# MCAN register map
Vendor: Texas Instruments
Peripheral module from a debugger description file (folder am574x).
Registers are 32-bit, access per field, reset 0x0 unless marked. A register's access mark holds for its fields unless they carry their own. Offsets are as the file gives them; lines under a group give offsets from that group; [hi:lo] are bit positions; {n}, {i} and the like mark numbered series; 'fields as' and 'values as' point back to an identical list; <NAME> marks a mode.

## MCAN (part 1 of 2)
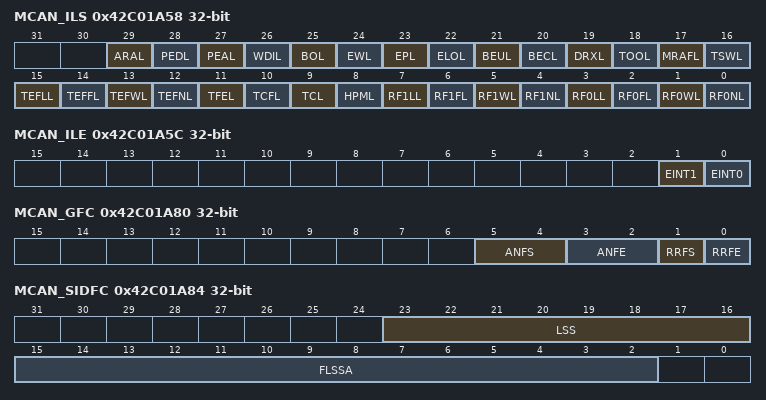
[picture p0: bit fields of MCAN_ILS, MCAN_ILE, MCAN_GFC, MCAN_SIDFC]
0x42C01A58 MCAN_ILS — Interrupt Line SelectThe Interrupt Line Select register assigns an interrupt generated by a specific interrupt flag from the Interrupt Register to one of the two module interrupt lines. For interrupt generation the respective interrupt line has to be enabled via the
  [29] ARAL rw — Access to Reserved Address Line 0x0: Interrupt assigned to interrupt line INT0 0x1: Interrupt assigned to interrupt line INT1
  [28] PEDL rw — Protocol Error in Data Phase Line 0x0: Interrupt assigned to interrupt line INT0 0x1: Interrupt assigned to interrupt line INT1
  [27] PEAL rw — Protocol Error in Arbitration Phase Line 0x0: Interrupt assigned to interrupt line INT0 0x1: Interrupt assigned to interrupt line INT1
  [26] WDIL rw — Watchdog Interrupt Line 0x0: Interrupt assigned to interrupt line INT0 0x1: Interrupt assigned to interrupt line INT1
  [25] BOL rw — Bus_Off Status Interrupt Line 0x0: Interrupt assigned to interrupt line INT0 0x1: Interrupt assigned to interrupt line INT1
  [24] EWL rw — Warning Status Interrupt Line 0x0: Interrupt assigned to interrupt line INT0 0x1: Interrupt assigned to interrupt line INT1
  [23] EPL rw — Error Passive Interrupt Line 0x0: Interrupt assigned to interrupt line INT0 0x1: Interrupt assigned to interrupt line INT1
  [22] ELOL rw — Error Logging Overflow Interrupt Line 0x0: Interrupt assigned to interrupt line INT0 0x1: Interrupt assigned to interrupt line INT1
  [21] BEUL rw — Bit Error Uncorrected Interrupt Line 0x0: Interrupt assigned to interrupt line INT0 0x1: Interrupt assigned to interrupt line INT1
  [20] BECL rw — Bit Error Corrected Interrupt Line 0x0: Interrupt assigned to interrupt line INT0 0x1: Interrupt assigned to interrupt line INT1
  [19] DRXL rw — Message stored to Dedicated Rx Buffer Interrupt Line 0x0: Interrupt assigned to interrupt line INT0 0x1: Interrupt assigned to interrupt line INT1
  [18] TOOL rw — Timeout Occurred Interrupt Line 0x0: Interrupt assigned to interrupt line INT0 0x1: Interrupt assigned to interrupt line INT1
  [17] MRAFL rw — Message RAM Access Failure Interrupt Line 0x0: Interrupt assigned to interrupt line INT0 0x1: Interrupt assigned to interrupt line INT1
  [16] TSWL rw — Timestamp Wraparound Interrupt Line 0x0: Interrupt assigned to interrupt line INT0 0x1: Interrupt assigned to interrupt line INT1
  [15] TEFLL rw — Tx Event FIFO Event Lost Interrupt Line 0x0: Interrupt assigned to interrupt line INT0 0x1: Interrupt assigned to interrupt line INT1
  [14] TEFFL rw — Tx Event FIFO Full Interrupt Line 0x0: Interrupt assigned to interrupt line INT0 0x1: Interrupt assigned to interrupt line INT1
  [13] TEFWL rw — Tx Event FIFO Watermark Reached Interrupt Line 0x0: Interrupt assigned to interrupt line INT0 0x1: Interrupt assigned to interrupt line INT1
  [12] TEFNL rw — Tx Event FIFO New Entry Interrupt Line 0x0: Interrupt assigned to interrupt line INT0 0x1: Interrupt assigned to interrupt line INT1
  [11] TFEL rw — Tx FIFO Empty Interrupt Line 0x0: Interrupt assigned to interrupt line INT0 0x1: Interrupt assigned to interrupt line INT1
  [10] TCFL rw — Transmission Cancellation Finished Interrupt Line 0x0: Interrupt assigned to interrupt line INT0 0x1: Interrupt assigned to interrupt line INT1
  [9] TCL rw — Transmission Completed Interrupt Line 0x0: Interrupt assigned to interrupt line INT0 0x1: Interrupt assigned to interrupt line INT1
  [8] HPML rw — High Priority Message Interrupt Line 0x0: Interrupt assigned to interrupt line INT0 0x1: Interrupt assigned to interrupt line INT1
  [7] RF1LL rw — Rx FIFO 1 Message Lost Interrupt Line 0x0: Interrupt assigned to interrupt line INT0 0x1: Interrupt assigned to interrupt line INT1
  [6] RF1FL rw — Rx FIFO 1 Full Interrupt Line 0x0: Interrupt assigned to interrupt line INT0 0x1: Interrupt assigned to interrupt line INT1
  [5] RF1WL rw — Rx FIFO 1 Watermark Reached Interrupt Line 0x0: Interrupt assigned to interrupt line INT0 0x1: Interrupt assigned to interrupt line INT1
  [4] RF1NL rw — Rx FIFO 1 New Message Interrupt Line 0x0: Interrupt assigned to interrupt line INT0 0x1: Interrupt assigned to interrupt line INT1
  [3] RF0LL rw — Rx FIFO 0 Message Lost Interrupt Line 0x0: Interrupt assigned to interrupt line INT0 0x1: Interrupt assigned to interrupt line INT1
  [2] RF0FL rw — Rx FIFO 0 Full Interrupt Line 0x0: Interrupt assigned to interrupt line INT0 0x1: Interrupt assigned to interrupt line INT1
  [1] RF0WL rw — Rx FIFO 0 Watermark Reached Interrupt Line 0x0: Interrupt assigned to interrupt line INT0 0x1: Interrupt assigned to interrupt line INT1
  [0] RF0NL rw — Rx FIFO 0 New Message Interrupt Line 0x0: Interrupt assigned to interrupt line INT0 0x1: Interrupt assigned to interrupt line INT1
0x42C01A5C MCAN_ILE — Interrupt Line Enable Enable/disable interrupt lines INT0/INT1. Each of the two interrupt lines to the Host CPU can be enabled/disabled separately by programming the
  [1] EINT1 rw — Enable Interrupt Line 1 0x0: Interrupt line INT1 disabled 0x1: Interrupt line INT1 enabled
  [0] EINT0 rw — Enable Interrupt Line 0 0x0: Interrupt line INT0 disabled 0x1: Interrupt line INT0 enabled
0x42C01A80 MCAN_GFC — Global Filter Configuration Handling of non-matching frames and remote frames. Global settings for Message ID filtering. The Global Filter Configuration controls the filter path for standard and extended messages (see
  [5:4] ANFS rw — Accept Non-matching Frames Standard Defines how received messages with 11-bit IDs that do not match any element of the filter list are treated. 0x0: Accept in Rx FIFO 0 0x1: Accept in Rx FIFO 1 0x2: Reject 0x3: Reject
  [3:2] ANFE rw — Accept Non-matching Frames Extended Defines how received messages with 29-bit IDs that do not match any element of the filter list are treated. 0x0: Accept in Rx FIFO 0 0x1: Accept in Rx FIFO 1 0x2: Reject 0x3: Reject
  [1] RRFS rw — Reject Remote Frames Standard 0x0: Filter remote frames with 11-bit standard IDs 0x1: Reject all remote frames with 11-bit standard IDs
  [0] RRFE rw — Reject Remote Frames Extended 0x0: Filter remote frames with 29-bit extended IDs 0x1: Reject all remote frames with 29-bit extended IDs
0x42C01A84 MCAN_SIDFC — Standard ID Filter Configuration Number of filter elements, pointer to start of filter list. Settings for 11-bit standard Message ID filtering. The Standard ID Filter Configuration controls the filter path for standard messages (see
  [23:16] LSS rw — List Size Standard 0x0: No standard Message ID filter 0x1-0x80 (1-128): Number of standard Message ID filter elements &gt; 0x80 (128): Values greater than 128 are interpreted as 128
  [15:2] FLSSA rw — Filter List Standard Start Address Start address of standard Message ID filter list (32-bit word address, see
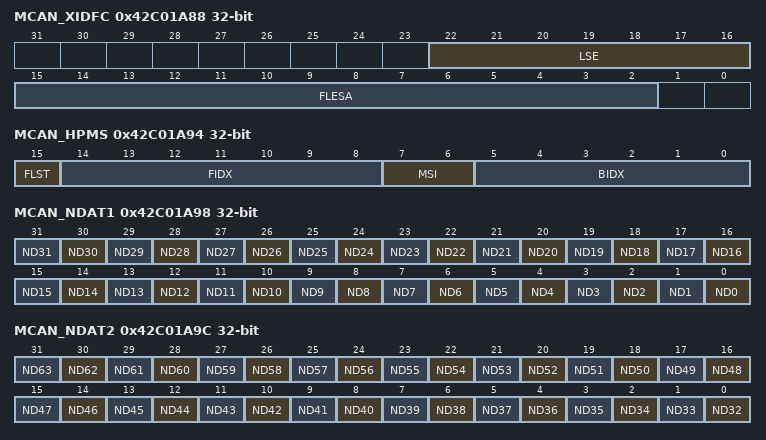
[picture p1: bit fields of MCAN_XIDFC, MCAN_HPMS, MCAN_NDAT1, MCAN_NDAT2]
0x42C01A88 MCAN_XIDFC — Extended ID Filter Configuration Number of filter elements, pointer to start of filter list. Settings for 29-bit extended Message ID filtering. The Extended ID Filter Configuration controls the filter path for standard messages (see
  [22:16] LSE rw — List Size Extended 0x0: No extended Message ID filter 0x1-0x40 (1-64): Number of extended Message ID filter elements &gt; 0x40 (64): Values greater than 64 are interpreted as 64
  [15:2] FLESA rw — Filter List Extended Start Address Start address of extended Message ID filter list (32-bit word address, see
0x42C01A90 MCAN_XIDAM reset 0x1FFFFFFF — Extended ID AND Mask 29-bit logical AND mask for J1939.
  [28:0] EIDM rw — Extended ID Mask For acceptance filtering of extended frames the Extended ID AND Mask is ANDed with the Message ID of a received frame. Intended for masking of 29-bit IDs in SAE J1939. With the reset value of all bits set to one the mask is not active.
0x42C01A94 MCAN_HPMS ro — High Priority Message Status Status monitoring of incoming high priority messages. This register is updated every time a Message ID filter element configured to generate a priority event matches. This can be used to monitor the status of incoming high priority messages and to enable fast access to these messages.
  [15] FLST — Filter List Indicates the filter list of the matching filter element. 0x0: Standard Filter List 0x1: Extended Filter List
  [14:8] FIDX — Filter Index Index of matching filter element. Range is 0 to
  [7:6] MSI — Message Storage Indicator 0x0: No FIFO selected 0x1: FIFO message lost 0x2: Message stored in FIFO 0 0x3: Message stored in FIFO 1
  [5:0] BIDX — Buffer Index Index of Rx FIFO element to which the message was stored. Only valid when the
0x42C01A98 MCAN_NDAT1 access not given — New Data 1 NewDat flags of dedicated Rx buffers 0-31. The register holds the New Data flags of Rx Buffers 0 to 31. The flags are set when the respective Rx Buffer has been updated from a received frame. The flags remain set until the Host CPU clears them. Aflag is cleared by writing a ’1’ to the corresponding bit position. Writing a ’0’ has no effect. Ahard reset will clear the register.
  [n] ND{n} (n=0..31) — New Data 0x0: Rx Buffer not updated 0x1: Rx Buffer updated from new message (access RW1TC)
0x42C01A9C MCAN_NDAT2 access not given — New Data 2 NewDat flags of dedicated Rx buffers 32-63. The register holds the New Data flags of Rx Buffers 32 to 63. The flags are set when the respective Rx Buffer has been updated from a received frame. The flags remain set until the Host CPU clears them. Aflag is cleared by writing a ’1’ to the corresponding bit position. Writing a ’0’ has no effect. Ahard reset will clear the register.
  [n-32] ND{n} (n=32..63) — New Data 0x0: Rx Buffer not updated 0x1: Rx Buffer updated from new message (access RW1TC)
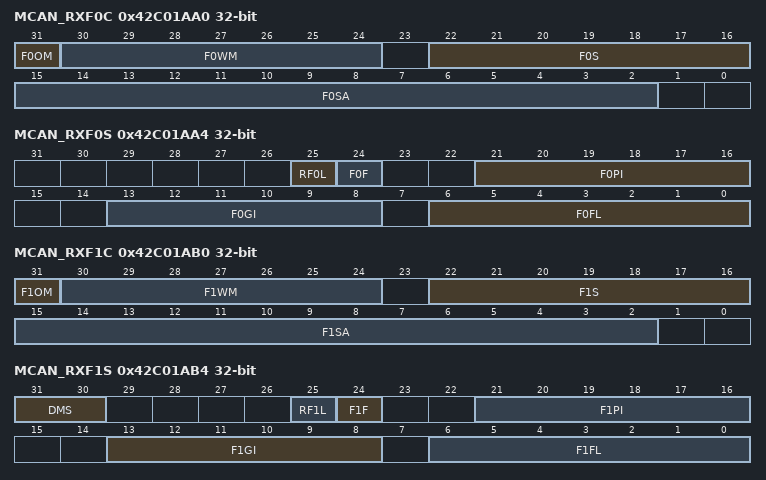
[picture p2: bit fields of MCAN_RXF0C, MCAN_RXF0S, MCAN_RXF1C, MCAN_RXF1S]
0x42C01AA0 MCAN_RXF0C — Rx FIFO 0 Configuration FIFO 0 operation mode, watermark, size and start address.
  [31] F0OM rw — FIFO 0 Operation Mode FIFO 0 can be operated in blocking or in overwrite mode (see 0x0: FIFO 0 blocking mode 0x1: FIFO 0 overwrite mode
  [30:24] F0WM rw — Rx FIFO 0 Watermark 0x0: Watermark interrupt disabled 0x1-0x40 (1-64): Level for Rx FIFO 0 watermark interrupt ( &gt; 0x40 (64): Watermark interrupt disabled
  [22:16] F0S rw — Rx FIFO 0 Size 0x0: No Rx FIFO 0 0x1-0x40 (1-64): Number of Rx FIFO 0 elements &gt; 0x40 (64): Values greater than 64 are interpreted as 64 The Rx FIFO 0 elements are indexed from 0 to
  [15:2] F0SA rw — Rx FIFO 0 Start Address Start address of Rx FIFO 0 in Message RAM (32-bit word address, see
0x42C01AA4 MCAN_RXF0S ro — Rx FIFO 0 Status FIFO 0 message lost/full indication, put index, get index and fill level.
  [25] RF0L — Rx FIFO 0 Message Lost This bit is a copy of interrupt flag 0x0: No Rx FIFO 0 message lost 0x1: Rx FIFO 0 message lost, also set after write attempt to Rx FIFO 0 of size zero
  [24] F0F — Rx FIFO 0 Full 0x0: Rx FIFO 0 not full 0x1: Rx FIFO 0 full
  [21:16] F0PI — Rx FIFO 0 Put Index Rx FIFO 0 write index pointer, range 0 to 63.
  [13:8] F0GI — Rx FIFO 0 Get Index Rx FIFO 0 read index pointer, range 0 to 63.
  [6:0] F0FL — Rx FIFO 0 Fill Level Number of elements stored in Rx FIFO 0, range 0 to 64.
0x42C01AA8 MCAN_RXF0A — Rx FIFO 0 Acknowledge FIFO 0 acknowledge last index of read buffers, updates get index and fill level.
  [5:0] F0AI rw — Rx FIFO 0 Acknowledge Index After the Host CPU has read a message or a sequence of messages from Rx FIFO 0 it has to write the buffer index of the last element read from Rx FIFO 0 to the
0x42C01AAC MCAN_RXBC — Rx Buffer Configuration Start address of Rx buffer section.
  [15:2] RBSA rw — Rx Buffer Start Address Configures the start address of the Rx Buffers section in the Message RAM Also used to reference debug messages A,B,C.
0x42C01AB0 MCAN_RXF1C — Rx FIFO 1 Configuration FIFO 1 operation mode, watermark, size and start address.
  [31] F1OM rw — FIFO 1 Operation Mode FIFO 1 can be operated in blocking or in overwrite mode (see 0x0: FIFO 1 blocking mode 0x1: FIFO 1 overwrite mode
  [30:24] F1WM rw — Rx FIFO 1 Watermark 0x0: Watermark interrupt disabled 0x1-0x40 (1-64): Level for Rx FIFO 1 watermark interrupt ( &gt; 0x40 (64): Watermark interrupt disabled
  [22:16] F1S rw — Rx FIFO 1 Size 0x0: No Rx FIFO 1 0x1-0x40 (1-64): Number of Rx FIFO 1 elements &gt; 0x40 (64): Values greater than 64 are interpreted as 64 The Rx FIFO 1 elements are indexed from 0 to
  [15:2] F1SA rw — Rx FIFO 1 Start Address Start address of Rx FIFO 1 in Message RAM (32-bit word address, see
0x42C01AB4 MCAN_RXF1S ro — Rx FIFO 1 Status FIFO 1 message lost/full indication, put index, get index and fill level.
  [31:30] DMS — Debug Message Status 0x0: Idle state, wait for reception of debug messages, DMA request is cleared 0x1: Debug message A received 0x2: Debug messages A, B received 0x3: Debug messages A, B, C received,
  [25] RF1L — Rx FIFO 1 Message Lost This bit is a copy of interrupt flag 0x0: No Rx FIFO 1 message lost 0x1: Rx FIFO 1 message lost, also set after write attempt to Rx FIFO 1 of size zero
  [24] F1F — Rx FIFO 1 Full 0x0: Rx FIFO 1 not full 0x1: Rx FIFO 1 full
  [21:16] F1PI — Rx FIFO 1 Put Index Rx FIFO 1 write index pointer, range 0 to 63.
  [13:8] F1GI — Rx FIFO 1 Get Index Rx FIFO 1 read index pointer, range 0 to 63.
  [6:0] F1FL — Rx FIFO 1 Fill Level Number of elements stored in Rx FIFO 1, range 0 to 64.
0x42C01AB8 MCAN_RXF1A — Rx FIFO 1 Acknowledge FIFO 1 acknowledge last index of read buffers, updates get index and fill level.
  [5:0] F1AI rw — Rx FIFO 1 Acknowledge Index After the Host CPU has read a message or a sequence of messages from Rx FIFO 1 it has to write the buffer index of the last element read from Rx FIFO 1 to the
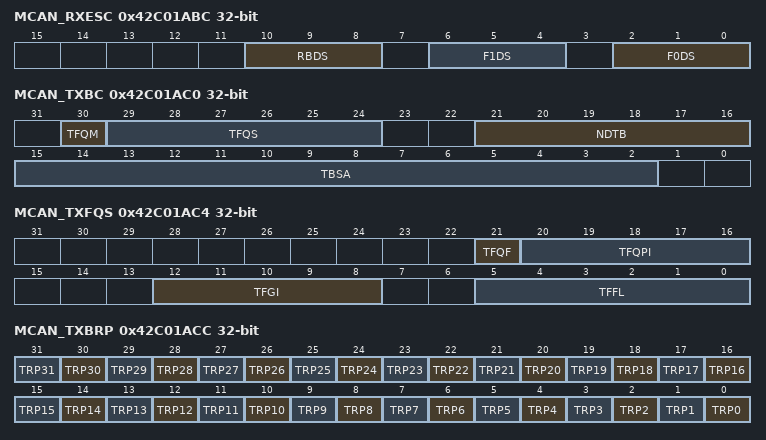
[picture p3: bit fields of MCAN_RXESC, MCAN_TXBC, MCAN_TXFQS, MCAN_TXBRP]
0x42C01ABC MCAN_RXESC — Rx Buffer/FIFO Element Size Configuration Configure data field size for storage of accepted frames.
  [10:8] RBDS rw — Rx Buffer Data Field Size 0x0: 8 byte data field 0x1: 12 byte data field 0x2: 16 byte data field 0x3: 20 byte data field 0x4: 24 byte data field 0x5: 32 byte data field 0x6: 48 byte data field 0x7: 64 byte data field
  [6:4] F1DS rw — Rx FIFO 1 Data Field Size 0x0: 8 byte data field 0x1: 12 byte data field 0x2: 16 byte data field 0x3: 20 byte data field 0x4: 24 byte data field 0x5: 32 byte data field 0x6: 48 byte data field 0x7: 64 byte data field
  [2:0] F0DS rw — Rx FIFO 0 Data Field Size 0x0: 8 byte data field 0x1: 12 byte data field 0x2: 16 byte data field 0x3: 20 byte data field 0x4: 24 byte data field 0x5: 32 byte data field 0x6: 48 byte data field 0x7: 64 byte data field
0x42C01AC0 MCAN_TXBC — Tx Buffer Configuration Configure Tx FIFO/Queue mode, Tx FIFO/Queue size, number of dedicated Tx buffers, Tx buffer start address.
  [30] TFQM rw — Tx FIFO/Queue Mode 0x0: Tx FIFO operation 0x1: Tx Queue operation
  [29:24] TFQS rw — Transmit FIFO/Queue Size 0x0: No Tx FIFO/Queue 0x1-0x20 (1-32): Number of Tx Buffers used for Tx FIFO/Queue &gt; 0x20 (32): Values greater than 32 are interpreted as 32
  [21:16] NDTB rw — Number of Dedicated Transmit Buffers 0x0: No Dedicated Tx Buffers 0x1-0x20 (1-32): Number of Dedicated Tx Buffers &gt; 0x20 (32): Values greater than 32 are interpreted as 32
  [15:2] TBSA rw — Tx Buffers Start Address Start address of Tx Buffers section in Message RAM (32-bit word address, see
0x42C01AC4 MCAN_TXFQS ro — Tx FIFO/Queue Status Tx FIFO/Queue full indication and put index, Tx FIFO get index and fill level. The Tx FIFO/Queue status is related to the pending Tx requests listed in the
  [21] TFQF — Tx FIFO/Queue Full 0x0: Tx FIFO/Queue not full 0x1: Tx FIFO/Queue full
  [20:16] TFQPI — Tx FIFO/Queue Put Index Tx FIFO/Queue write index pointer, range 0 to 31.
  [12:8] TFGI — Tx FIFO Get Index Tx FIFO read index pointer, range 0 to 31. Read as zero when Tx Queue operation is configured (
  [5:0] TFFL — Tx FIFO Free Level Number of consecutive free Tx FIFO elements starting from the
0x42C01AC8 MCAN_TXESC — Tx Buffer Element Size Configuration Configure data field size for frame transmission. Configures the number of data bytes belonging to a Tx Buffer element. Data field sizes > 8 bytes are intended for CAN FD operation only.
  [2:0] TBDS rw — Tx Buffer Data Field Size 0x0: 8 byte data field 0x1: 12 byte data field 0x2: 16 byte data field 0x3: 20 byte data field 0x4: 24 byte data field 0x5: 32 byte data field 0x6: 48 byte data field 0x7: 64 byte data field
0x42C01ACC MCAN_TXBRP ro — Tx Buffer Request Pending Tx buffers with pending transmission request. Each Tx Buffer has its own Transmission Request Pending bit. The bits are set via the The A cancellation request resets the corresponding transmission request pending bit of register the After a cancellation has been requested, a finished cancellation is signalled via the • after successful transmission together with the corresponding • when the transmission has not yet been started at the point of cancellation • when the transmission has been aborted due to lost arbitration • when an error occurred during frame transmission In DAR mode all transmissions are automatically cancelled if they are not successful. The corresponding
  [n] TRP{n} (n=0..31) — Transmission Request Pending 0x0: No transmission request pending 0x1: Transmission request pending
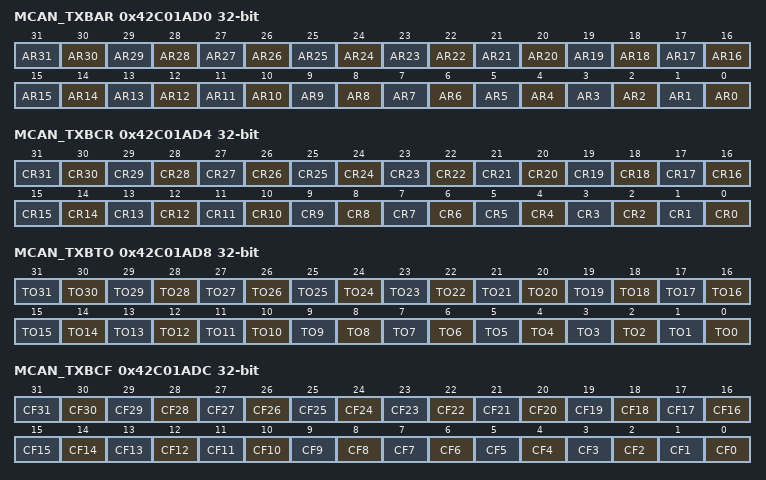
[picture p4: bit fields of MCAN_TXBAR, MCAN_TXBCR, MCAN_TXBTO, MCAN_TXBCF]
0x42C01AD0 MCAN_TXBAR access not given — Tx Buffer Add Request Add transmission requests. Each Tx Buffer has its own Add Request bit. Writing a ‘1’ will set the corresponding Add Request bit; writing a ‘0’ has no impact. This enables the Host CPU to set transmission requests for multiple Tx Buffers with one write to the
  [n] AR{n} (n=0..31) — Add Request 0x0: No transmission request added 0x1: Transmission requested added (access RW1TC)
0x42C01AD4 MCAN_TXBCR access not given — Tx Buffer Cancellation Request Request cancellation of pending transmissions. Each Tx Buffer has its own Cancellation Request bit. Writing a ‘1’ will set the corresponding Cancellation Request bit; writing a ‘0’ has no impact. This enables the Host CPU to set cancellation requests for multiple Tx Buffers with one write to the
  [n] CR{n} (n=0..31) — Cancellation Request 0x0: No cancellation pending 0x1: Cancellation pending (access RW1TC)
0x42C01AD8 MCAN_TXBTO ro — Tx Buffer Transmission Occurred Signals successful transmissions, set when corresponding flag is cleared. Each Tx Buffer has its own Transmission Occurred bit. The bits are set when the corresponding
  [n] TO{n} (n=0..31) — Transmission Occurred 0x0: No transmission occurred 0x1: Transmission occurred
0x42C01ADC MCAN_TXBCF ro — Tx Buffer Cancellation Finished Signals successful transmit cancellation, set when corresponding TXBRP flag is cleared after cancellation request. Each Tx Buffer has its own Cancellation Finished bit. The bits are set when the corresponding
  [n] CF{n} (n=0..31) — Cancellation Finished 0x0: No transmit buffer cancellation 0x1: Transmit buffer cancellation finished
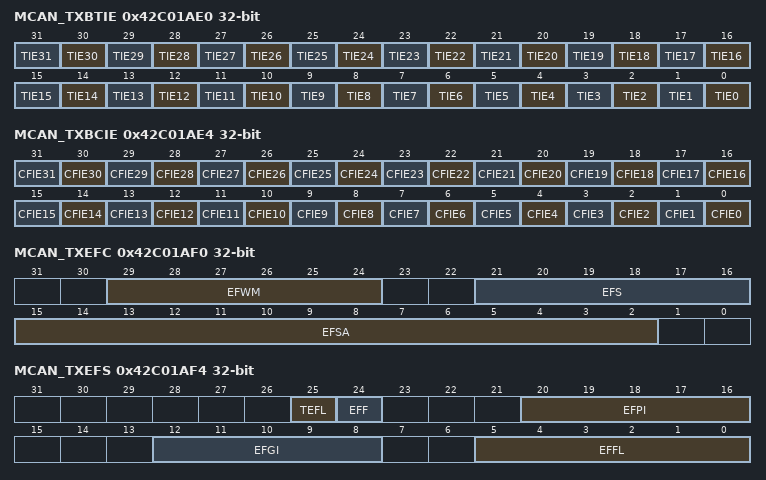
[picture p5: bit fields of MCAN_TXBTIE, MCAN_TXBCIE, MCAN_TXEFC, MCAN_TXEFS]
0x42C01AE0 MCAN_TXBTIE rw — Tx Buffer Transmission Interrupt Enable Enable transmit interrupts for selected Tx buffers.
  [n] TIE{n} (n=0..31) — Transmission Interrupt Enable 0x0: Transmission interrupt disabled 0x1: Transmission interrupt enable
0x42C01AE4 MCAN_TXBCIE rw — Tx Buffer Cancellation Finished Interrupt Enable Enable cancellation finished interrupts for selected Tx buffers.
  [n] CFIE{n} (n=0..31) — Cancellation Finished Interrupt Enable 0x0: Cancellation finished interrupt disabled 0x1: Cancellation finished interrupt enabled
0x42C01AF0 MCAN_TXEFC — Tx Event FIFO Configuration Tx event FIFO watermark, size and start address.
  [29:24] EFWM rw — Event FIFO Watermark 0x0: Watermark interrupt disabled 0x1-0x20 (1-32): Level for Tx Event FIFO watermark interrupt ( &gt; 0x20 (32): Watermark interrupt disabled
  [21:16] EFS rw — Event FIFO Size 0x0: Tx Event FIFO disabled 0x1-0x20 (1-32): Number of Tx Event FIFO elements &gt; 0x20 (32): Values greater than 32 are interpreted as 32 The Tx Event FIFO elements are indexed from 0 to
  [15:2] EFSA rw — Event FIFO Start Address Start address of Tx Event FIFO in Message RAM (32-bit word address, see
0x42C01AF4 MCAN_TXEFS ro — Tx Event FIFO Status Tx event FIFO element lost/full indication, put index, get index, and fill level.
  [25] TEFL — This bit is a copy of interrupt flag 0x0: No Tx Event FIFO element lost 0x1: Tx Event FIFO element lost, also set after write attempt to Tx Event FIFO of size zero.
  [24] EFF — Event FIFO Full 0x0: Tx Event FIFO not full 0x1: Tx Event FIFO full
  [20:16] EFPI — Event FIFO Put Index Tx Event FIFO write index pointer, range 0 to 31.
  [12:8] EFGI — Event FIFO Get Index Tx Event FIFO read index pointer, range 0 to 31.
  [5:0] EFFL — Event FIFO Fill Level Number of elements stored in Tx Event FIFO, range 0 to 32.
0x42C01AF8 MCAN_TXEFA — Tx Event FIFO Acknowledge Tx event FIFO acknowledge last index of read elements, updates get index and fill level.
  [4:0] EFAI rw — After the Host CPU has read an element or a sequence of elements from the Tx Event FIFO it has to write the index of the last element read from Tx Event FIFO to the
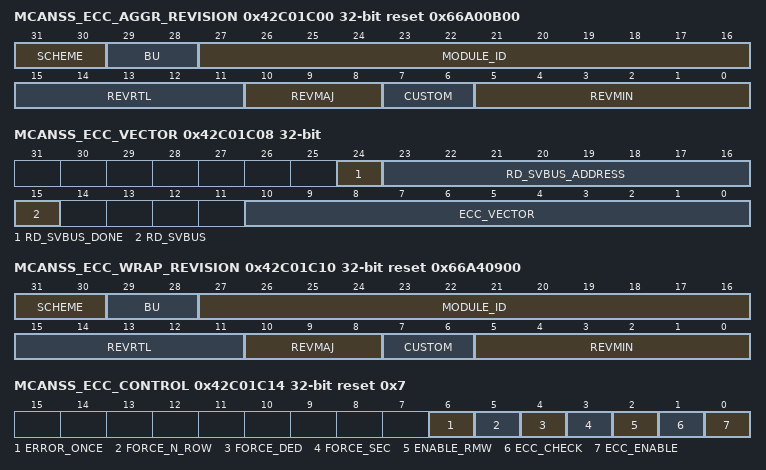
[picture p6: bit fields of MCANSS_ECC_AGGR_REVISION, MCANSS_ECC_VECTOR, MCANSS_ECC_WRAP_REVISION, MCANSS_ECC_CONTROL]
0x42C01C00 MCANSS_ECC_AGGR_REVISION ro reset 0x66A00B00 — Aggregator Revision Register Revision parameters.
  [31:30] SCHEME
  [29:28] BU — Business Unit
  [27:16] MODULE_ID
  [15:11] REVRTL — RTL version
  [10:8] REVMAJ — Major version
  [7:6] CUSTOM — Custom version
  [5:0] REVMIN — Minor version
0x42C01C08 MCANSS_ECC_VECTOR — ECC Vector Register ECC Vector Register.
  [24] RD_SVBUS_DONE ro — Status to indicate if read is complete
  [23:16] RD_SVBUS_ADDRESS rw — Read address
  [15] RD_SVBUS rw — Write 1 to trigger a read
  [10:0] ECC_VECTOR rw — Value written to select the corresponding ECC RAM for control or status
0x42C01C0C MCANSS_ECC_MISC_STATUS ro reset 0x1 — Misc Status Misc Status.
  [10:0] NUM_RAMS — Indicates the number of RAMS serviced by the ECC aggregator
0x42C01C10 MCANSS_ECC_WRAP_REVISION ro reset 0x66A40900 — ECC Wrapper Revision Register Revision parameters.
  fields as MCANSS_ECC_AGGR_REVISION
0x42C01C14 MCANSS_ECC_CONTROL reset 0x7 — ECC Control ECC Control Register.
  [6] ERROR_ONCE rw — Force Error only once
  [5] FORCE_N_ROW rw — Force Error on any RAM read
  [4] FORCE_DED rw — Force Double Bit Error
  [3] FORCE_SEC rw — Force Single Bit Error
  [2] ENABLE_RMW rw
  [1] ECC_CHECK rw — Enable ECC check
  [0] ECC_ENABLE rw — Enable ECC
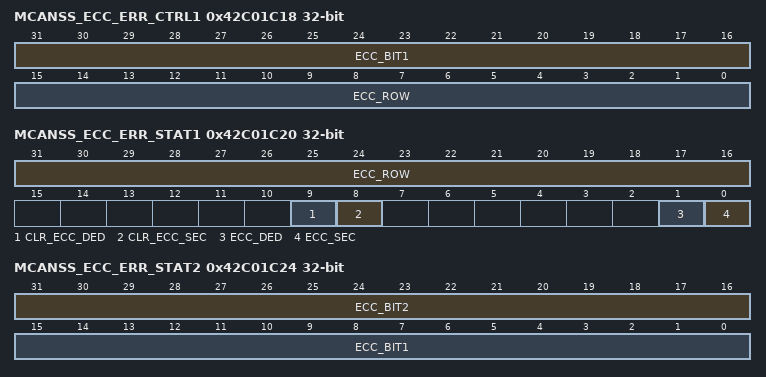
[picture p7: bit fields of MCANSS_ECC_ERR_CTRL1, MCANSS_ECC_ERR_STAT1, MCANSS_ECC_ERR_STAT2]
0x42C01C18 MCANSS_ECC_ERR_CTRL1 rw — ECC Error Control1 Register ECC Error Control1 Register.
  [31:16] ECC_BIT1 — Data bit that needs to be flipped when FORCE_SEC is set
  [15:0] ECC_ROW — Row address where single or double-bit error needs to be applied. This is ignored if FORCE_N_ROW is set.
0x42C01C1C MCANSS_ECC_ERR_CTRL2 — ECC Error Control2 Register ECC Error Control2 Register.
  [15:0] ECC_BIT2 rw — Data bit that needs to be flipped if double bit error needs to be forced
0x42C01C20 MCANSS_ECC_ERR_STAT1 access not given — ECC Error Status1 Register ECC Error Status1 Register.
  [31:16] ECC_ROW ro — Row address where the single or double-bit error has occurred
  [9] CLR_ECC_DED — Clear Double Bit Error Status (access RW1TC)
  [8] CLR_ECC_SEC — Clear Single Bit Error Status (access RW1TC)
  [1] ECC_DED — Level Double Bit Error Status (access RW1TS)
  [0] ECC_SEC — Level Single Bit Error Status (access RW1TS)
0x42C01C24 MCANSS_ECC_ERR_STAT2 ro — ECC Error Status2 Register ECC Error Status2 Register.
  [31:16] ECC_BIT2 — Data bit that corresponds to the double-bit error
  [15:0] ECC_BIT1 — Data bit that corresponds to the single-bit error
0x42C01C3C MCANSS_ECC_SEC_EOI_REG — EOI Register EOI Register.
  [0] EOI_WR rw — EOI Register
0x42C01C40 MCANSS_ECC_SEC_STATUS_REG0 access not given — Interrupt Status Register 0 Interrupt Status Register 0.
  [0] MSGMEM_PEND — Interrupt Pending Status for MSGMEM_PEND (access RW1TS)
0x42C01C80 MCANSS_ECC_SEC_ENABLE_SET_REG0 access not given — Interrupt Enable Set Register 0 Interrupt Enable Set Register 0.
  [0] MSGMEM_ENABLE_SET — Interrupt Enable Set Register for MSGMEM_PEND (access RW1TS)
0x42C01CC0 MCANSS_ECC_SEC_ENABLE_CLR_REG0 access not given — Interrupt Enable Clear Register 0 Interrupt Enable Clear Register 0.
  [0] MSGMEM_ENABLE_CLR — Interrupt Enable Clear Register for MSGMEM_PEND (access RW1TC)
0x42C01D3C MCANSS_ECC_DED_EOI_REG — EOI Register EOI Register.
  [0] EOI_WR rw — EOI Register
0x42C01D40 MCANSS_ECC_DED_STATUS_REG0 access not given — Interrupt Status Register 0 Interrupt Status Register 0.
  fields as MCANSS_ECC_SEC_STATUS_REG0
0x42C01D80 MCANSS_ECC_DED_ENABLE_SET_REG0 access not given — Interrupt Enable Set Register 0 Interrupt Enable Set Register 0.
  fields as MCANSS_ECC_SEC_ENABLE_SET_REG0
0x42C01DC0 MCANSS_ECC_DED_ENABLE_CLR_REG0 access not given — Interrupt Enable Clear Register 0 Interrupt Enable Clear Register 0.
  fields as MCANSS_ECC_SEC_ENABLE_CLR_REG0
